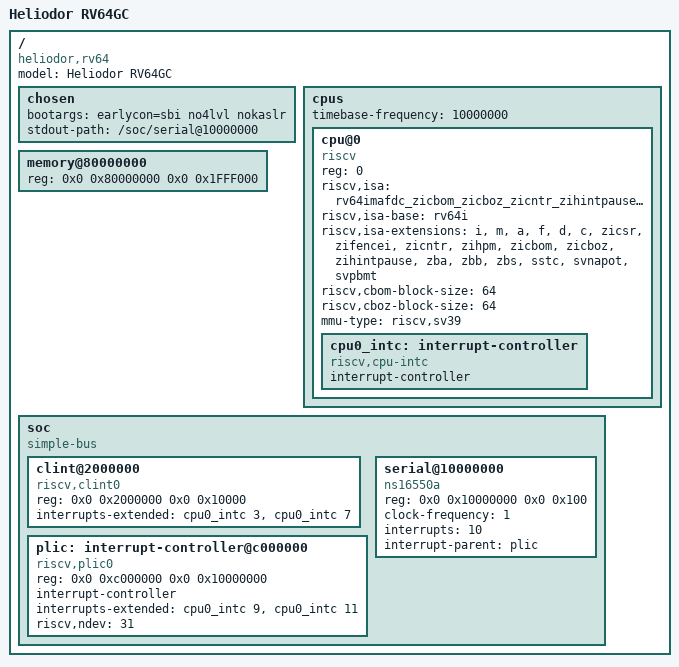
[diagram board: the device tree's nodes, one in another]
/dts-v1/;

/* Heliodor DTS for Linux 6.6 RVA23 verification (1-hart).
 * Advertises the RVA23 ISA extensions heliodor implements so the 6.6 kernel
 * exercises them during boot:
 *   Sstc (stimecmp timer), Zba/Zbb/Zbs, Zicbom/Zicboz (+ block sizes),
 *   Svpbmt, Svnapot, Zihintpause, Zicntr/Zihpm.
 * Svinval/Svadu/Zawrs are deferred to the 7.1 stage. */

/ {
	#address-cells = <2>;
	#size-cells = <2>;
	compatible = "heliodor,rv64";
	model = "Heliodor RV64GC";

	chosen {
		bootargs = "earlycon=sbi no4lvl nokaslr";
		stdout-path = "/soc/serial@10000000";
	};

	cpus {
		#address-cells = <1>;
		#size-cells = <0>;
		timebase-frequency = <10000000>;

		cpu@0 {
			device_type = "cpu";
			compatible = "riscv";
			reg = <0>;
			/* Linux 6.6 device-tree boot uses riscv,isa-extensions (the
			 * legacy riscv,isa string is only consulted with
			 * CONFIG_RISCV_ISA_FALLBACK). Provide both. */
			riscv,isa = "rv64imafdc_zicbom_zicboz_zicntr_zihintpause_zihpm_zba_zbb_zbs_sstc_svnapot_svpbmt";
			riscv,isa-base = "rv64i";
			riscv,isa-extensions = "i", "m", "a", "f", "d", "c",
				"zicsr", "zifencei", "zicntr", "zihpm",
				"zicbom", "zicboz", "zihintpause",
				"zba", "zbb", "zbs",
				"sstc", "svnapot", "svpbmt";
			riscv,cbom-block-size = <64>;
			riscv,cboz-block-size = <64>;
			mmu-type = "riscv,sv39";
			status = "okay";

			cpu0_intc: interrupt-controller {
				#interrupt-cells = <1>;
				compatible = "riscv,cpu-intc";
				interrupt-controller;
			};
		};
	};

	memory@80000000 {
		device_type = "memory";
		reg = <0x0 0x80000000 0x0 0x1FFF000>;
	};

	soc {
		#address-cells = <2>;
		#size-cells = <2>;
		compatible = "simple-bus";
		ranges;

		clint@2000000 {
			compatible = "riscv,clint0";
			reg = <0x0 0x2000000 0x0 0x10000>;
			interrupts-extended = <&cpu0_intc 3>, <&cpu0_intc 7>;
		};

		plic: interrupt-controller@c000000 {
			compatible = "riscv,plic0";
			reg = <0x0 0xc000000 0x0 0x10000000>;
			#interrupt-cells = <1>;
			interrupt-controller;
			interrupts-extended = <&cpu0_intc 9>, <&cpu0_intc 11>;
			riscv,ndev = <31>;
		};

		serial@10000000 {
			compatible = "ns16550a";
			reg = <0x0 0x10000000 0x0 0x100>;
			clock-frequency = <1>;
			interrupts = <10>;
			interrupt-parent = <&plic>;
		};
	};
};
